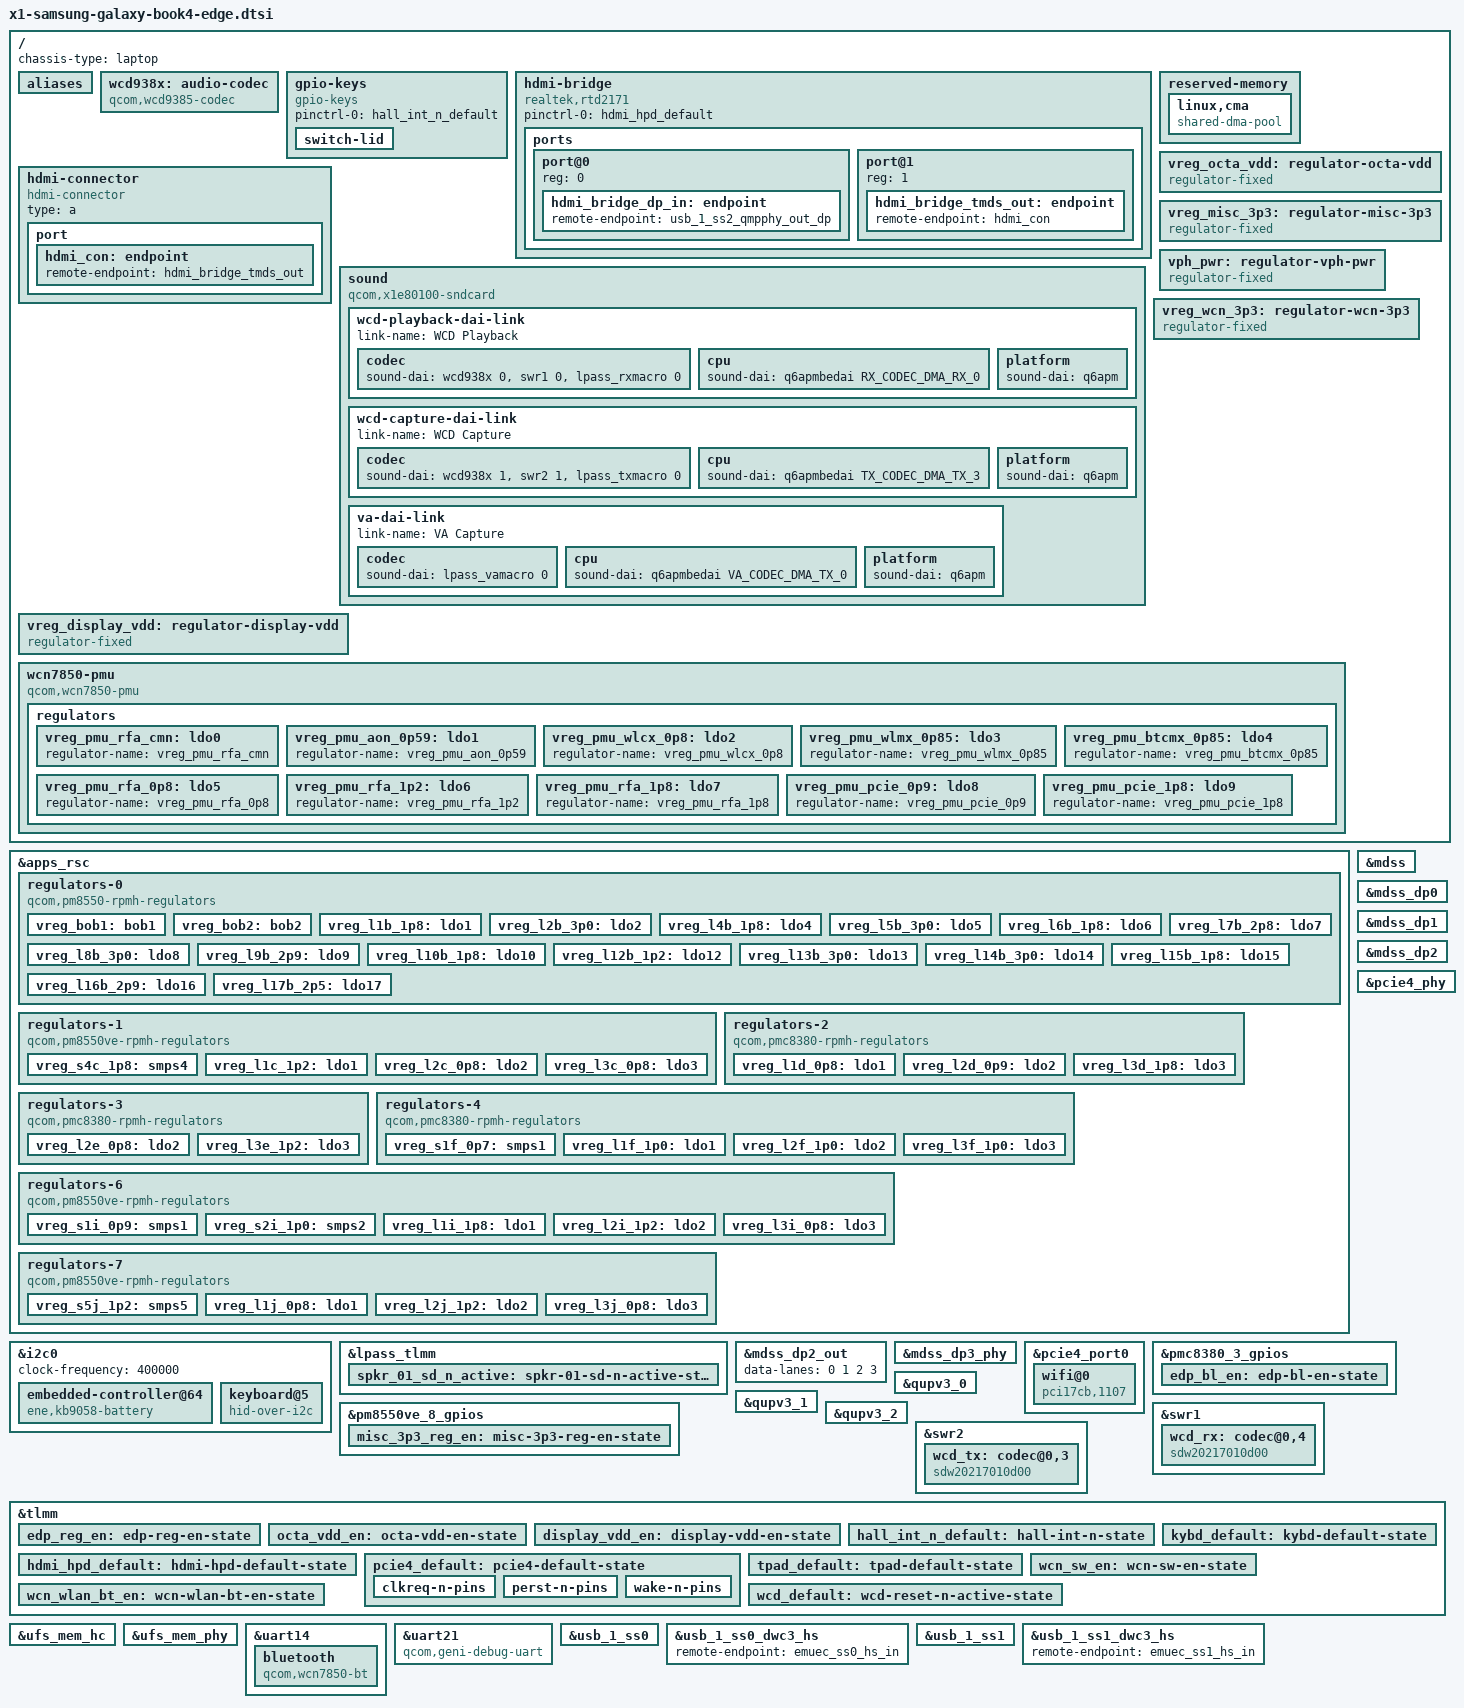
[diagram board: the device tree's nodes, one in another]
// SPDX-License-Identifier: BSD-3-Clause
/*
 * Copyright (c) 2023 Qualcomm Innovation Center, Inc. All rights reserved.
 * Copyright (c) 2025 Kirill A. Korinsky <kirill@korins.ky>
 * Copyright (c) 2025 Valentin Manea <valentin.manea@mrs.ro>
 * Copyright (c) 2026 Antheas Kapenekakis <lkml@antheas.dev>
 */

#include <dt-bindings/gpio/gpio.h>
#include <dt-bindings/input/gpio-keys.h>
#include <dt-bindings/input/input.h>
#include <dt-bindings/pinctrl/qcom,pmic-gpio.h>
#include <dt-bindings/regulator/qcom,rpmh-regulator.h>

/ {
	chassis-type = "laptop";

	aliases {
		serial0 = &uart21;
		serial1 = &uart14;
	};

	wcd938x: audio-codec {
		compatible = "qcom,wcd9385-codec";

		pinctrl-0 = <&wcd_default>;
		pinctrl-names = "default";

		qcom,micbias1-microvolt = <1800000>;
		qcom,micbias2-microvolt = <1800000>;
		qcom,micbias3-microvolt = <1800000>;
		qcom,micbias4-microvolt = <1800000>;
		qcom,mbhc-buttons-vthreshold-microvolt = <75000 150000 237000 500000
						     500000 500000 500000 500000>;
		qcom,mbhc-headset-vthreshold-microvolt = <1700000>;
		qcom,mbhc-headphone-vthreshold-microvolt = <50000>;
		qcom,rx-device = <&wcd_rx>;
		qcom,tx-device = <&wcd_tx>;

		reset-gpios = <&tlmm 191 GPIO_ACTIVE_LOW>;

		vdd-buck-supply = <&vreg_l15b_1p8>;
		vdd-rxtx-supply = <&vreg_l15b_1p8>;
		vdd-io-supply = <&vreg_l15b_1p8>;
		vdd-mic-bias-supply = <&vreg_bob1>;

		#sound-dai-cells = <1>;
	};

	gpio-keys {
		compatible = "gpio-keys";

		pinctrl-0 = <&hall_int_n_default>;
		pinctrl-names = "default";

		switch-lid {
			gpios = <&tlmm 92 GPIO_ACTIVE_LOW>;
			linux,input-type = <EV_SW>;
			linux,code = <SW_LID>;
			wakeup-source;
			wakeup-event-action = <EV_ACT_DEASSERTED>;
		};
	};

	hdmi-bridge {
		compatible = "realtek,rtd2171";

		pinctrl-0 = <&hdmi_hpd_default>;
		pinctrl-names = "default";

		ports {
			#address-cells = <1>;
			#size-cells = <0>;

			port@0 {
				reg = <0>;

				hdmi_bridge_dp_in: endpoint {
					remote-endpoint = <&usb_1_ss2_qmpphy_out_dp>;
				};
			};

			port@1 {
				reg = <1>;

				hdmi_bridge_tmds_out: endpoint {
					remote-endpoint = <&hdmi_con>;
				};
			};
		};
	};

	hdmi-connector {
		compatible = "hdmi-connector";
		type = "a";

		port {
			hdmi_con: endpoint {
				remote-endpoint = <&hdmi_bridge_tmds_out>;
			};
		};
	};

	reserved-memory {
		linux,cma {
			compatible = "shared-dma-pool";
			size = <0x0 0x8000000>;
			reusable;
			linux,cma-default;
		};
	};

	sound {
		compatible = "qcom,x1e80100-sndcard";

		wcd-playback-dai-link {
			link-name = "WCD Playback";

			codec {
				sound-dai = <&wcd938x 0>, <&swr1 0>, <&lpass_rxmacro 0>;
			};

			cpu {
				sound-dai = <&q6apmbedai RX_CODEC_DMA_RX_0>;
			};

			platform {
				sound-dai = <&q6apm>;
			};
		};

		wcd-capture-dai-link {
			link-name = "WCD Capture";

			codec {
				sound-dai = <&wcd938x 1>, <&swr2 1>, <&lpass_txmacro 0>;
			};

			cpu {
				sound-dai = <&q6apmbedai TX_CODEC_DMA_TX_3>;
			};

			platform {
				sound-dai = <&q6apm>;
			};
		};

		va-dai-link {
			link-name = "VA Capture";

			codec {
				sound-dai = <&lpass_vamacro 0>;
			};

			cpu {
				sound-dai = <&q6apmbedai VA_CODEC_DMA_TX_0>;
			};

			platform {
				sound-dai = <&q6apm>;
			};
		};
	};

	vreg_octa_vdd: regulator-octa-vdd {
		compatible = "regulator-fixed";

		regulator-name = "VREG_OCTA_VDD";
		regulator-min-microvolt = <1800000>;
		regulator-max-microvolt = <1800000>;

		gpio = <&tlmm 111 GPIO_ACTIVE_HIGH>;
		enable-active-high;

		pinctrl-0 = <&octa_vdd_en>;
		pinctrl-names = "default";

		startup-delay-us = <1000>;
		regulator-enable-ramp-delay = <1000>;

		regulator-always-on;
		regulator-boot-on;
	};

	vreg_display_vdd: regulator-display-vdd {
		compatible = "regulator-fixed";

		regulator-name = "VREG_DISPLAY_VDD";
		regulator-min-microvolt = <3300000>;
		regulator-max-microvolt = <3300000>;

		gpio = <&tlmm 120 GPIO_ACTIVE_HIGH>;
		enable-active-high;

		pinctrl-0 = <&display_vdd_en>;
		pinctrl-names = "default";

		startup-delay-us = <400000>;
		regulator-enable-ramp-delay = <400000>;

		vin-supply = <&vreg_octa_vdd>;

		regulator-always-on;
		regulator-boot-on;
	};

	vreg_misc_3p3: regulator-misc-3p3 {
		compatible = "regulator-fixed";

		regulator-name = "VREG_MISC_3P3";
		regulator-min-microvolt = <3300000>;
		regulator-max-microvolt = <3300000>;

		gpio = <&pm8550ve_8_gpios 6 GPIO_ACTIVE_HIGH>;
		enable-active-high;

		pinctrl-0 = <&misc_3p3_reg_en>;
		pinctrl-names = "default";

		regulator-boot-on;
		regulator-always-on;
	};

	vph_pwr: regulator-vph-pwr {
		compatible = "regulator-fixed";

		regulator-name = "vph_pwr";
		regulator-min-microvolt = <3700000>;
		regulator-max-microvolt = <3700000>;

		regulator-always-on;
		regulator-boot-on;
	};

	vreg_wcn_3p3: regulator-wcn-3p3 {
		compatible = "regulator-fixed";

		regulator-name = "VREG_WCN_3P3";
		regulator-min-microvolt = <3300000>;
		regulator-max-microvolt = <3300000>;

		gpio = <&tlmm 214 GPIO_ACTIVE_HIGH>;
		enable-active-high;

		pinctrl-0 = <&wcn_sw_en>;
		pinctrl-names = "default";

		regulator-boot-on;
		regulator-always-on;
	};

	wcn7850-pmu {
		compatible = "qcom,wcn7850-pmu";
		wlan-enable-gpios = <&tlmm 117 GPIO_ACTIVE_HIGH>;
		bt-enable-gpios = <&tlmm 116 GPIO_ACTIVE_HIGH>;
		pinctrl-0 = <&wcn_wlan_bt_en>;
		pinctrl-names = "default";

		regulators {
			vreg_pmu_rfa_cmn: ldo0 {
				regulator-name = "vreg_pmu_rfa_cmn";
			};

			vreg_pmu_aon_0p59: ldo1 {
				regulator-name = "vreg_pmu_aon_0p59";
			};

			vreg_pmu_wlcx_0p8: ldo2 {
				regulator-name = "vreg_pmu_wlcx_0p8";
			};

			vreg_pmu_wlmx_0p85: ldo3 {
				regulator-name = "vreg_pmu_wlmx_0p85";
			};

			vreg_pmu_btcmx_0p85: ldo4 {
				regulator-name = "vreg_pmu_btcmx_0p85";
			};

			vreg_pmu_rfa_0p8: ldo5 {
				regulator-name = "vreg_pmu_rfa_0p8";
			};

			vreg_pmu_rfa_1p2: ldo6 {
				regulator-name = "vreg_pmu_rfa_1p2";
			};

			vreg_pmu_rfa_1p8: ldo7 {
				regulator-name = "vreg_pmu_rfa_1p8";
			};

			vreg_pmu_pcie_0p9: ldo8 {
				regulator-name = "vreg_pmu_pcie_0p9";
			};

			vreg_pmu_pcie_1p8: ldo9 {
				regulator-name = "vreg_pmu_pcie_1p8";
			};
		};
	};
};

&apps_rsc {
	regulators-0 {
		compatible = "qcom,pm8550-rpmh-regulators";
		qcom,pmic-id = "b";

		vdd-bob1-supply = <&vph_pwr>;
		vdd-bob2-supply = <&vph_pwr>;
		vdd-l1-l4-l10-supply = <&vreg_s4c_1p8>;
		vdd-l2-l13-l14-supply = <&vreg_bob1>;
		vdd-l5-l16-supply = <&vreg_bob1>;
		vdd-l6-l7-supply = <&vreg_bob2>;
		vdd-l8-l9-supply = <&vreg_bob1>;
		vdd-l12-supply = <&vreg_s5j_1p2>;
		vdd-l15-supply = <&vreg_s4c_1p8>;
		vdd-l17-supply = <&vreg_bob2>;

		vreg_bob1: bob1 {
			regulator-name = "vreg_bob1";
			regulator-min-microvolt = <3008000>;
			regulator-max-microvolt = <3960000>;
			regulator-initial-mode = <RPMH_REGULATOR_MODE_HPM>;
		};

		vreg_bob2: bob2 {
			regulator-name = "vreg_bob2";
			regulator-min-microvolt = <2504000>;
			regulator-max-microvolt = <3008000>;
			regulator-initial-mode = <RPMH_REGULATOR_MODE_HPM>;
		};

		vreg_l1b_1p8: ldo1 {
			regulator-name = "vreg_l1b_1p8";
			regulator-min-microvolt = <1800000>;
			regulator-max-microvolt = <1800000>;
			regulator-initial-mode = <RPMH_REGULATOR_MODE_HPM>;
		};

		vreg_l2b_3p0: ldo2 {
			regulator-name = "vreg_l2b_3p0";
			regulator-min-microvolt = <3072000>;
			regulator-max-microvolt = <3100000>;
			regulator-initial-mode = <RPMH_REGULATOR_MODE_HPM>;
		};

		vreg_l4b_1p8: ldo4 {
			regulator-name = "vreg_l4b_1p8";
			regulator-min-microvolt = <1800000>;
			regulator-max-microvolt = <1800000>;
			regulator-initial-mode = <RPMH_REGULATOR_MODE_HPM>;
		};

		vreg_l5b_3p0: ldo5 {
			regulator-name = "vreg_l5b_3p0";
			regulator-min-microvolt = <3000000>;
			regulator-max-microvolt = <3000000>;
			regulator-initial-mode = <RPMH_REGULATOR_MODE_HPM>;
		};

		vreg_l6b_1p8: ldo6 {
			regulator-name = "vreg_l6b_1p8";
			regulator-min-microvolt = <1800000>;
			regulator-max-microvolt = <2960000>;
			regulator-initial-mode = <RPMH_REGULATOR_MODE_HPM>;
		};

		vreg_l7b_2p8: ldo7 {
			regulator-name = "vreg_l7b_2p8";
			regulator-always-on;
			regulator-min-microvolt = <2800000>;
			regulator-max-microvolt = <2800000>;
			regulator-initial-mode = <RPMH_REGULATOR_MODE_HPM>;
		};

		vreg_l8b_3p0: ldo8 {
			regulator-name = "vreg_l8b_3p0";
			regulator-min-microvolt = <3072000>;
			regulator-max-microvolt = <3072000>;
			regulator-initial-mode = <RPMH_REGULATOR_MODE_HPM>;
		};

		vreg_l9b_2p9: ldo9 {
			regulator-name = "vreg_l9b_2p9";
			regulator-min-microvolt = <2960000>;
			regulator-max-microvolt = <2960000>;
			regulator-initial-mode = <RPMH_REGULATOR_MODE_HPM>;
		};

		vreg_l10b_1p8: ldo10 {
			regulator-name = "vreg_l10b_1p8";
			regulator-always-on;
			regulator-min-microvolt = <1800000>;
			regulator-max-microvolt = <1800000>;
			regulator-initial-mode = <RPMH_REGULATOR_MODE_HPM>;
		};

		vreg_l12b_1p2: ldo12 {
			regulator-name = "vreg_l12b_1p2";
			regulator-min-microvolt = <1200000>;
			regulator-max-microvolt = <1200000>;
			regulator-initial-mode = <RPMH_REGULATOR_MODE_HPM>;
			regulator-always-on;
		};

		vreg_l13b_3p0: ldo13 {
			regulator-name = "vreg_l13b_3p0";
			regulator-min-microvolt = <3072000>;
			regulator-max-microvolt = <3100000>;
			regulator-initial-mode = <RPMH_REGULATOR_MODE_HPM>;
		};

		vreg_l14b_3p0: ldo14 {
			regulator-name = "vreg_l14b_3p0";
			regulator-min-microvolt = <3072000>;
			regulator-max-microvolt = <3072000>;
			regulator-initial-mode = <RPMH_REGULATOR_MODE_HPM>;
		};

		vreg_l15b_1p8: ldo15 {
			regulator-name = "vreg_l15b_1p8";
			regulator-min-microvolt = <1800000>;
			regulator-max-microvolt = <1800000>;
			regulator-initial-mode = <RPMH_REGULATOR_MODE_HPM>;
			regulator-always-on;
		};

		vreg_l16b_2p9: ldo16 {
			regulator-name = "vreg_l16b_2p9";
			regulator-min-microvolt = <2912000>;
			regulator-max-microvolt = <2912000>;
			regulator-initial-mode = <RPMH_REGULATOR_MODE_HPM>;
		};

		vreg_l17b_2p5: ldo17 {
			regulator-name = "vreg_l17b_2p5";
			regulator-min-microvolt = <2504000>;
			regulator-max-microvolt = <2504000>;
			regulator-initial-mode = <RPMH_REGULATOR_MODE_HPM>;
		};
	};

	regulators-1 {
		compatible = "qcom,pm8550ve-rpmh-regulators";
		qcom,pmic-id = "c";

		vdd-l1-supply = <&vreg_s5j_1p2>;
		vdd-l2-supply = <&vreg_s1f_0p7>;
		vdd-l3-supply = <&vreg_s1f_0p7>;
		vdd-s4-supply = <&vph_pwr>;

		vreg_s4c_1p8: smps4 {
			regulator-name = "vreg_s4c_1p8";
			regulator-min-microvolt = <1856000>;
			regulator-max-microvolt = <2000000>;
			regulator-initial-mode = <RPMH_REGULATOR_MODE_HPM>;
		};

		vreg_l1c_1p2: ldo1 {
			regulator-name = "vreg_l1c_1p2";
			regulator-min-microvolt = <1200000>;
			regulator-max-microvolt = <1200000>;
			regulator-initial-mode = <RPMH_REGULATOR_MODE_HPM>;
		};

		vreg_l2c_0p8: ldo2 {
			regulator-name = "vreg_l2c_0p8";
			regulator-min-microvolt = <880000>;
			regulator-max-microvolt = <920000>;
			regulator-initial-mode = <RPMH_REGULATOR_MODE_HPM>;
		};

		vreg_l3c_0p8: ldo3 {
			regulator-name = "vreg_l3c_0p8";
			regulator-min-microvolt = <880000>;
			regulator-max-microvolt = <920000>;
			regulator-initial-mode = <RPMH_REGULATOR_MODE_HPM>;
		};
	};

	regulators-2 {
		compatible = "qcom,pmc8380-rpmh-regulators";
		qcom,pmic-id = "d";

		vdd-l1-supply = <&vreg_s1f_0p7>;
		vdd-l2-supply = <&vreg_s1f_0p7>;
		vdd-l3-supply = <&vreg_s4c_1p8>;
		vdd-s1-supply = <&vph_pwr>;

		vreg_l1d_0p8: ldo1 {
			regulator-name = "vreg_l1d_0p8";
			regulator-min-microvolt = <880000>;
			regulator-max-microvolt = <920000>;
			regulator-initial-mode = <RPMH_REGULATOR_MODE_HPM>;
		};

		vreg_l2d_0p9: ldo2 {
			regulator-name = "vreg_l2d_0p9";
			regulator-min-microvolt = <912000>;
			regulator-max-microvolt = <920000>;
			regulator-initial-mode = <RPMH_REGULATOR_MODE_HPM>;
		};

		vreg_l3d_1p8: ldo3 {
			regulator-name = "vreg_l3d_1p8";
			regulator-min-microvolt = <1800000>;
			regulator-max-microvolt = <1800000>;
			regulator-initial-mode = <RPMH_REGULATOR_MODE_HPM>;
		};
	};

	regulators-3 {
		compatible = "qcom,pmc8380-rpmh-regulators";
		qcom,pmic-id = "e";

		vdd-l2-supply = <&vreg_s1f_0p7>;
		vdd-l3-supply = <&vreg_s5j_1p2>;

		vreg_l2e_0p8: ldo2 {
			regulator-name = "vreg_l2e_0p8";
			regulator-min-microvolt = <880000>;
			regulator-max-microvolt = <920000>;
			regulator-initial-mode = <RPMH_REGULATOR_MODE_HPM>;
		};

		vreg_l3e_1p2: ldo3 {
			regulator-name = "vreg_l3e_1p2";
			regulator-min-microvolt = <1200000>;
			regulator-max-microvolt = <1200000>;
			regulator-initial-mode = <RPMH_REGULATOR_MODE_HPM>;
		};
	};

	regulators-4 {
		compatible = "qcom,pmc8380-rpmh-regulators";
		qcom,pmic-id = "f";

		vdd-l1-supply = <&vreg_s5j_1p2>;
		vdd-l2-supply = <&vreg_s5j_1p2>;
		vdd-l3-supply = <&vreg_s5j_1p2>;
		vdd-s1-supply = <&vph_pwr>;

		vreg_s1f_0p7: smps1 {
			regulator-name = "vreg_s1f_0p7";
			regulator-min-microvolt = <700000>;
			regulator-max-microvolt = <1100000>;
			regulator-initial-mode = <RPMH_REGULATOR_MODE_HPM>;
		};

		vreg_l1f_1p0: ldo1 {
			regulator-name = "vreg_l1f_1p0";
			regulator-min-microvolt = <1024000>;
			regulator-max-microvolt = <1024000>;
			regulator-initial-mode = <RPMH_REGULATOR_MODE_HPM>;
		};

		vreg_l2f_1p0: ldo2 {
			regulator-name = "vreg_l2f_1p0";
			regulator-min-microvolt = <1024000>;
			regulator-max-microvolt = <1024000>;
			regulator-initial-mode = <RPMH_REGULATOR_MODE_HPM>;
		};

		vreg_l3f_1p0: ldo3 {
			regulator-name = "vreg_l3f_1p0";
			regulator-min-microvolt = <1024000>;
			regulator-max-microvolt = <1024000>;
			regulator-initial-mode = <RPMH_REGULATOR_MODE_HPM>;
		};
	};

	regulators-6 {
		compatible = "qcom,pm8550ve-rpmh-regulators";
		qcom,pmic-id = "i";

		vdd-l1-supply = <&vreg_s4c_1p8>;
		vdd-l2-supply = <&vreg_s5j_1p2>;
		vdd-l3-supply = <&vreg_s1f_0p7>;
		vdd-s1-supply = <&vph_pwr>;
		vdd-s2-supply = <&vph_pwr>;

		vreg_s1i_0p9: smps1 {
			regulator-name = "vreg_s1i_0p9";
			regulator-min-microvolt = <900000>;
			regulator-max-microvolt = <920000>;
			regulator-initial-mode = <RPMH_REGULATOR_MODE_HPM>;
		};

		vreg_s2i_1p0: smps2 {
			regulator-name = "vreg_s2i_1p0";
			regulator-min-microvolt = <1000000>;
			regulator-max-microvolt = <1100000>;
			regulator-initial-mode = <RPMH_REGULATOR_MODE_HPM>;
		};

		vreg_l1i_1p8: ldo1 {
			regulator-name = "vreg_l1i_1p8";
			regulator-min-microvolt = <1800000>;
			regulator-max-microvolt = <1800000>;
			regulator-initial-mode = <RPMH_REGULATOR_MODE_HPM>;
		};

		vreg_l2i_1p2: ldo2 {
			regulator-name = "vreg_l2i_1p2";
			regulator-min-microvolt = <1200000>;
			regulator-max-microvolt = <1200000>;
			regulator-initial-mode = <RPMH_REGULATOR_MODE_HPM>;
		};

		vreg_l3i_0p8: ldo3 {
			regulator-name = "vreg_l3i_0p8";
			regulator-min-microvolt = <880000>;
			regulator-max-microvolt = <920000>;
			regulator-initial-mode = <RPMH_REGULATOR_MODE_HPM>;
		};
	};

	regulators-7 {
		compatible = "qcom,pm8550ve-rpmh-regulators";
		qcom,pmic-id = "j";

		vdd-l1-supply = <&vreg_s1f_0p7>;
		vdd-l2-supply = <&vreg_s5j_1p2>;
		vdd-l3-supply = <&vreg_s1f_0p7>;
		vdd-s5-supply = <&vph_pwr>;

		vreg_s5j_1p2: smps5 {
			regulator-name = "vreg_s5j_1p2";
			regulator-min-microvolt = <1256000>;
			regulator-max-microvolt = <1304000>;
			regulator-initial-mode = <RPMH_REGULATOR_MODE_HPM>;
		};

		vreg_l1j_0p8: ldo1 {
			regulator-name = "vreg_l1j_0p8";
			regulator-min-microvolt = <880000>;
			regulator-max-microvolt = <920000>;
			regulator-initial-mode = <RPMH_REGULATOR_MODE_HPM>;
		};

		vreg_l2j_1p2: ldo2 {
			regulator-name = "vreg_l2j_1p2";
			regulator-min-microvolt = <1256000>;
			regulator-max-microvolt = <1256000>;
			regulator-initial-mode = <RPMH_REGULATOR_MODE_HPM>;
		};

		vreg_l3j_0p8: ldo3 {
			regulator-name = "vreg_l3j_0p8";
			regulator-min-microvolt = <880000>;
			regulator-max-microvolt = <920000>;
			regulator-initial-mode = <RPMH_REGULATOR_MODE_HPM>;
		};
	};
};

&i2c0 {
	clock-frequency = <400000>;
	status = "okay";

	embedded-controller@64 {
		compatible = "ene,kb9058-battery";
		reg = <0x64>;
		interrupts-extended = <&tlmm 66 IRQ_TYPE_EDGE_FALLING>;
	};

	keyboard@5 {
		compatible = "hid-over-i2c";
		reg = <0x5>;
		hid-descr-addr = <0x20>;
		interrupts-extended = <&tlmm 67 IRQ_TYPE_LEVEL_LOW>;
		pinctrl-0 = <&kybd_default>;
		pinctrl-names = "default";
		wakeup-source;
	};
};

&lpass_tlmm {
	spkr_01_sd_n_active: spkr-01-sd-n-active-state {
		pins = "gpio12";
		function = "gpio";
		drive-strength = <16>;
		bias-disable;
		output-low;
	};
};

&mdss {
	status = "okay";
};

&mdss_dp0 {
	status = "okay";
};

&mdss_dp1 {
	status = "okay";
};

&mdss_dp2 {
	status = "okay";
};

&mdss_dp2_out {
	data-lanes = <0 1 2 3>;
};

&mdss_dp3_phy {
	vdda-phy-supply = <&vreg_l3j_0p8>;
	vdda-pll-supply = <&vreg_l2j_1p2>;

	status = "okay";
};

&pcie4_phy {
	vdda-phy-supply = <&vreg_l3i_0p8>;
	vdda-pll-supply = <&vreg_l3e_1p2>;

	status = "okay";
};

&pcie4_port0 {
	wifi@0 {
		compatible = "pci17cb,1107";
		reg = <0x10000 0x0 0x0 0x0 0x0>;

		vddaon-supply = <&vreg_pmu_aon_0p59>;
		vddwlcx-supply = <&vreg_pmu_wlcx_0p8>;
		vddwlmx-supply = <&vreg_pmu_wlmx_0p85>;
		vddrfacmn-supply = <&vreg_pmu_rfa_cmn>;
		vddrfa0p8-supply = <&vreg_pmu_rfa_0p8>;
		vddrfa1p2-supply = <&vreg_pmu_rfa_1p2>;
		vddrfa1p8-supply = <&vreg_pmu_rfa_1p8>;
		vddpcie0p9-supply = <&vreg_pmu_pcie_0p9>;
		vddpcie1p8-supply = <&vreg_pmu_pcie_1p8>;
	};
};

&pm8550ve_8_gpios {
	misc_3p3_reg_en: misc-3p3-reg-en-state {
		pins = "gpio6";
		function = "normal";
		bias-disable;
		input-disable;
		output-enable;
		drive-push-pull;
		power-source = <1>; /* 1.8 V */
		qcom,drive-strength = <PMIC_GPIO_STRENGTH_LOW>;
	};
};

&pmc8380_3_gpios {
	edp_bl_en: edp-bl-en-state {
		pins = "gpio4";
		function = "normal";
		power-source = <1>; /* 1.8V */
		input-disable;
		output-enable;
	};
};

&qupv3_0 {
	status = "okay";
};

&qupv3_1 {
	status = "okay";
};

&qupv3_2 {
	status = "okay";
};

&swr1 {
	status = "okay";

	/* WCD9385 RX */
	wcd_rx: codec@0,4 {
		compatible = "sdw20217010d00";
		reg = <0 4>;
		qcom,rx-port-mapping = <1 2 3 4 5>;
	};
};

&swr2 {
	status = "okay";

	/* WCD9385 TX */
	wcd_tx: codec@0,3 {
		compatible = "sdw20217010d00";
		reg = <0 3>;
		qcom,tx-port-mapping = <2 2 3 4>;
	};
};

&tlmm {
 /* SPI (TPM) */

	edp_reg_en: edp-reg-en-state {
		pins = "gpio70";
		function = "gpio";
		drive-strength = <16>;
		bias-pull-up;
		output-low;
	};

	octa_vdd_en: octa-vdd-en-state {
		pins = "gpio111";
		function = "gpio";
		drive-strength = <16>;
		bias-pull-up;
		output-high;
	};

	display_vdd_en: display-vdd-en-state {
		pins = "gpio120";
		function = "gpio";
		drive-strength = <16>;
		bias-pull-up;
		output-high;
	};

	hall_int_n_default: hall-int-n-state {
		pins = "gpio92";
		function = "gpio";
		bias-disable;
	};

	kybd_default: kybd-default-state {
		pins = "gpio67";
		function = "gpio";
		bias-disable;
	};

	hdmi_hpd_default: hdmi-hpd-default-state {
		pins = "gpio126";
		function = "usb2_dp";
		bias-disable;
	};

	pcie4_default: pcie4-default-state {
		clkreq-n-pins {
			pins = "gpio147";
			function = "pcie4_clk";
			drive-strength = <2>;
			bias-pull-up;
		};

		perst-n-pins {
			pins = "gpio146";
			function = "gpio";
			drive-strength = <2>;
			bias-disable;
		};

		wake-n-pins {
			pins = "gpio148";
			function = "gpio";
			drive-strength = <2>;
			bias-pull-up;
		};
	};

	tpad_default: tpad-default-state {
		pins = "gpio3";
		function = "gpio";
		bias-disable;
	};

	wcn_sw_en: wcn-sw-en-state {
		pins = "gpio214";
		function = "gpio";
		drive-strength = <2>;
		bias-disable;
	};

	wcn_wlan_bt_en: wcn-wlan-bt-en-state {
		pins = "gpio116", "gpio117";
		function = "gpio";
		drive-strength = <2>;
		bias-disable;
	};

	wcd_default: wcd-reset-n-active-state {
		pins = "gpio191";
		function = "gpio";
		drive-strength = <16>;
		bias-disable;
		output-low;
	};
};

&ufs_mem_hc {
	status = "okay";

	reset-gpios = <&tlmm 238 GPIO_ACTIVE_LOW>;
	vcc-supply = <&vreg_l17b_2p5>;
	vcc-max-microamp = <600000>;

	vccq-supply = <&vreg_l2i_1p2>;
	vccq-max-microamp = <600000>;
};

&ufs_mem_phy {
	status = "okay";

	vdda-phy-supply = <&vreg_l3i_0p8>;
	vdda-pll-supply = <&vreg_l3e_1p2>;
};

&uart14 {
	status = "okay";

	bluetooth {
		compatible = "qcom,wcn7850-bt";
		max-speed = <3200000>;

		vddaon-supply = <&vreg_pmu_aon_0p59>;
		vddwlcx-supply = <&vreg_pmu_wlcx_0p8>;
		vddwlmx-supply = <&vreg_pmu_wlmx_0p85>;
		vddrfacmn-supply = <&vreg_pmu_rfa_cmn>;
		vddrfa0p8-supply = <&vreg_pmu_rfa_0p8>;
		vddrfa1p2-supply = <&vreg_pmu_rfa_1p2>;
		vddrfa1p8-supply = <&vreg_pmu_rfa_1p8>;
	};
};

&uart21 {
	compatible = "qcom,geni-debug-uart";
	status = "okay";
};

&usb_1_ss0 {
	status = "okay";
	dr_mode = "otg";
	usb-role-switch;
};

&usb_1_ss0_dwc3_hs {
	remote-endpoint = <&emuec_ss0_hs_in>;
};

&usb_1_ss1 {
	status = "okay";
	dr_mode = "otg";
	usb-role-switch;
};

&usb_1_ss1_dwc3_hs {
	remote-endpoint = <&emuec_ss1_hs_in>;
};
